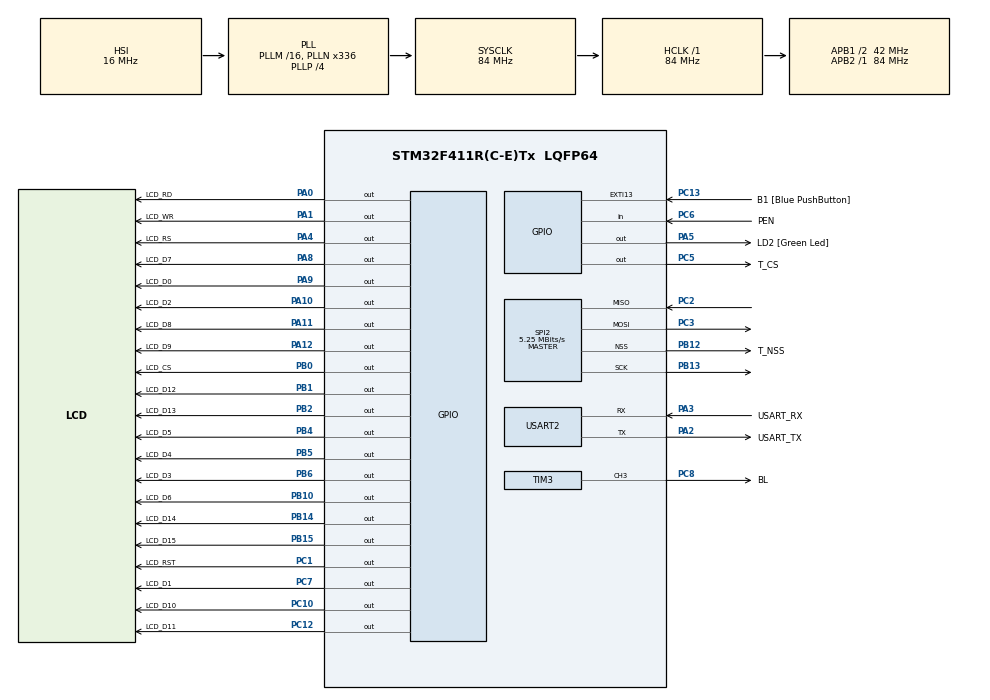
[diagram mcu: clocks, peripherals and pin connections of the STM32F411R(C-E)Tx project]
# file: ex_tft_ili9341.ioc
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Mcu.Family=STM32F4
Mcu.Name=STM32F411R(C-E)Tx
Mcu.Package=LQFP64
NVIC.EXTI15_10_IRQn=true\:0\:0\:false\:false\:true\:true\:true\:true
NVIC.PriorityGroup=NVIC_PRIORITYGROUP_0
NVIC.TIM2_IRQn=true\:0\:0\:false\:false\:true\:true\:true\:true
NVIC.TIM3_IRQn=true\:0\:0\:false\:false\:true\:true\:true\:true
NVIC.USART2_IRQn=true\:0\:0\:false\:false\:true\:true\:true\:true
PA0-WKUP.GPIO_Label=LCD_RD
PA0-WKUP.GPIO_PuPd=GPIO_NOPULL
PA0-WKUP.GPIO_Speed=GPIO_SPEED_FREQ_LOW
PA0-WKUP.Signal=GPIO_Output
PA1.GPIO_Label=LCD_WR
PA1.GPIO_PuPd=GPIO_NOPULL
PA1.GPIO_Speed=GPIO_SPEED_FREQ_LOW
PA1.Signal=GPIO_Output
PA10.GPIO_Label=LCD_D2
PA10.GPIO_PuPd=GPIO_NOPULL
PA10.GPIO_Speed=GPIO_SPEED_FREQ_LOW
PA10.Signal=GPIO_Output
PA11.GPIO_Label=LCD_D8
PA11.GPIO_PuPd=GPIO_NOPULL
PA11.GPIO_Speed=GPIO_SPEED_FREQ_LOW
PA11.Signal=GPIO_Output
PA12.GPIO_Label=LCD_D9
PA12.GPIO_PuPd=GPIO_NOPULL
PA12.GPIO_Speed=GPIO_SPEED_FREQ_LOW
PA12.Signal=GPIO_Output
PA13.GPIO_Label=TMS
PA13.Mode=Serial_Wire
PA13.Signal=SYS_JTMS-SWDIO
PA14.GPIO_Label=TCK
PA14.Mode=Serial_Wire
PA14.Signal=SYS_JTCK-SWCLK
PA2.GPIO_Label=USART_TX
PA2.Mode=Asynchronous
PA2.Signal=USART2_TX
PA3.GPIO_Label=USART_RX
PA3.Mode=Asynchronous
PA3.Signal=USART2_RX
PA4.GPIO_Label=LCD_RS
PA4.GPIO_PuPd=GPIO_NOPULL
PA4.GPIO_Speed=GPIO_SPEED_FREQ_LOW
PA4.Signal=GPIO_Output
PA5.GPIO_Label=LD2 [Green Led]
PA5.Signal=GPIO_Output
PA8.GPIO_Label=LCD_D7
PA8.GPIO_PuPd=GPIO_NOPULL
PA8.GPIO_Speed=GPIO_SPEED_FREQ_LOW
PA8.Signal=GPIO_Output
PA9.GPIO_Label=LCD_D0
PA9.GPIO_PuPd=GPIO_NOPULL
PA9.GPIO_Speed=GPIO_SPEED_FREQ_LOW
PA9.Signal=GPIO_Output
PB0.GPIO_Label=LCD_CS
PB0.GPIO_PuPd=GPIO_NOPULL
PB0.GPIO_Speed=GPIO_SPEED_FREQ_LOW
PB0.Signal=GPIO_Output
PB1.GPIO_Label=LCD_D12
PB1.GPIO_PuPd=GPIO_NOPULL
PB1.GPIO_Speed=GPIO_SPEED_FREQ_LOW
PB1.Signal=GPIO_Output
PB10.GPIO_Label=LCD_D6
PB10.GPIO_PuPd=GPIO_NOPULL
PB10.GPIO_Speed=GPIO_SPEED_FREQ_LOW
PB10.Signal=GPIO_Output
PB12.GPIO_Label=T_NSS
PB12.Mode=NSS_Signal_Hard_Output
PB12.Signal=SPI2_NSS
PB13.Mode=Full_Duplex_Master
PB13.Signal=SPI2_SCK
PB14.GPIO_Label=LCD_D14
PB14.GPIO_PuPd=GPIO_NOPULL
PB14.GPIO_Speed=GPIO_SPEED_FREQ_LOW
PB14.Signal=GPIO_Output
PB15.GPIO_Label=LCD_D15
PB15.GPIO_PuPd=GPIO_NOPULL
PB15.GPIO_Speed=GPIO_SPEED_FREQ_LOW
PB15.Signal=GPIO_Output
PB2.GPIO_Label=LCD_D13
PB2.GPIO_PuPd=GPIO_NOPULL
PB2.GPIO_Speed=GPIO_SPEED_FREQ_LOW
PB2.Signal=GPIO_Output
PB4.GPIO_Label=LCD_D5
PB4.GPIO_PuPd=GPIO_NOPULL
PB4.GPIO_Speed=GPIO_SPEED_FREQ_LOW
PB4.Signal=GPIO_Output
PB5.GPIO_Label=LCD_D4
PB5.GPIO_PuPd=GPIO_NOPULL
PB5.GPIO_Speed=GPIO_SPEED_FREQ_LOW
PB5.Signal=GPIO_Output
PB6.GPIO_Label=LCD_D3
PB6.GPIO_PuPd=GPIO_NOPULL
PB6.Signal=GPIO_Output
PC1.GPIO_Label=LCD_RST
PC1.GPIO_PuPd=GPIO_NOPULL
PC1.GPIO_Speed=GPIO_SPEED_FREQ_LOW
PC1.Signal=GPIO_Output
PC10.GPIO_Label=LCD_D10
PC10.GPIO_PuPd=GPIO_NOPULL
PC10.GPIO_Speed=GPIO_SPEED_FREQ_LOW
PC10.Signal=GPIO_Output
PC12.GPIO_Label=LCD_D11
PC12.GPIO_PuPd=GPIO_NOPULL
PC12.Signal=GPIO_Output
PC13-ANTI_TAMP.GPIO_Label=B1 [Blue PushButton]
PC13-ANTI_TAMP.GPIO_ModeDefaultEXTI=GPIO_MODE_IT_FALLING
PC13-ANTI_TAMP.Signal=GPXTI13
PC14-OSC32_IN.Mode=LSE-External-Oscillator
PC14-OSC32_IN.Signal=RCC_OSC32_IN
PC15-OSC32_OUT.Mode=LSE-External-Oscillator
PC15-OSC32_OUT.Signal=RCC_OSC32_OUT
PC2.Mode=Full_Duplex_Master
PC2.Signal=SPI2_MISO
PC3.Mode=Full_Duplex_Master
PC3.Signal=SPI2_MOSI
PC5.GPIO_Label=T_CS
PC5.GPIO_PuPd=GPIO_NOPULL
PC5.Signal=GPIO_Output
PC6.GPIO_Label=PEN
PC6.GPIO_PuPd=GPIO_NOPULL
PC6.Signal=GPIO_Input
PC7.GPIO_Label=LCD_D1
PC7.GPIO_PuPd=GPIO_NOPULL
PC7.Signal=GPIO_Output
PC8.GPIO_Label=BL
PC8.Signal=S_TIM3_CH3
PH0\ -\ OSC_IN.Mode=HSE-External-Clock-Source
PH0\ -\ OSC_IN.Signal=RCC_OSC_IN
PH1\ -\ OSC_OUT.Mode=HSE-External-Clock-Source
PH1\ -\ OSC_OUT.Signal=RCC_OSC_OUT
ProjectManager.HeapSize=0x200
ProjectManager.StackSize=0x400
ProjectManager.TargetToolchain=STM32CubeIDE
RCC.48MHZClocksFreq_Value=84000000
RCC.AHBFreq_Value=84000000
RCC.APB1CLKDivider=RCC_HCLK_DIV2
RCC.APB1Freq_Value=42000000
RCC.APB1TimFreq_Value=84000000
RCC.APB2Freq_Value=84000000
RCC.APB2TimFreq_Value=84000000
RCC.CortexFreq_Value=84000000
RCC.FLatency-AdvancedSettings=FLASH_LATENCY_2
RCC.HCLKFreq_Value=84000000
RCC.HSE_VALUE=8000000
RCC.HSI_VALUE=16000000
RCC.PLLN=336
RCC.PLLP=RCC_PLLP_DIV4
RCC.SYSCLKFreq_VALUE=84000000
RCC.SYSCLKSource=RCC_SYSCLKSOURCE_PLLCLK
RCC.VCOOutputFreq_Value=336000000
SH.S_TIM3_CH3.0=TIM3_CH3,PWM Generation3 CH3
SPI2.BaudRatePrescaler=SPI_BAUDRATEPRESCALER_8
SPI2.CLKPhase=SPI_PHASE_1EDGE
SPI2.CLKPolarity=SPI_POLARITY_LOW
SPI2.CalculateBaudRate=5.25 MBits/s
SPI2.Direction=SPI_DIRECTION_2LINES
SPI2.Mode=SPI_MODE_MASTER
SPI2.TIMode=SPI_TIMODE_DISABLE
SPI2.VirtualNSS=VM_NSSHARD
SPI2.VirtualType=VM_MASTER
TIM2.Prescaler=84-1
TIM3.Channel-PWM\ Generation3\ CH3=TIM_CHANNEL_3
TIM3.Period=1000
TIM3.Prescaler=84-1
TIM3.Pulse-PWM\ Generation3\ CH3=500
USART2.VirtualMode=VM_ASYNC
VP_TIM2_VS_ClockSourceINT.Mode=Internal
VP_TIM3_VS_ClockSourceINT.Mode=Internal
board=NUCLEO-F411RE

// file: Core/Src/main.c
/* USER CODE BEGIN Header */
/**
  ******************************************************************************
  * @file           : main.c
  * @brief          : Main program body
  ******************************************************************************
  * @attention
  *
  * Copyright (c) 2023 STMicroelectronics.
  * All rights reserved.
  *
  * This software is licensed under terms that can be found in the LICENSE file
  * in the root directory of this software component.
  * If no LICENSE file comes with this software, it is provided AS-IS.
  *
  ******************************************************************************
  */
/* USER CODE END Header */
#include "main.h"

/* USER CODE BEGIN Includes */
#include "app_port.h"

/* USER CODE END Includes */

SPI_HandleTypeDef hspi2;

TIM_HandleTypeDef htim2;
TIM_HandleTypeDef htim3;

UART_HandleTypeDef huart2;

void SystemClock_Config(void);
static void MX_GPIO_Init(void);
static void MX_USART2_UART_Init(void);
static void MX_TIM2_Init(void);
static void MX_SPI2_Init(void);
static void MX_TIM3_Init(void);

int main(void)
{

  /* MCU Configuration--------------------------------------------------------*/

  /* Reset of all peripherals, Initializes the Flash interface and the Systick. */
  HAL_Init();

  /* Configure the system clock */
  SystemClock_Config();

  /* Initialize all configured peripherals */
  MX_GPIO_Init();
  MX_USART2_UART_Init();
  MX_TIM2_Init();
  MX_SPI2_Init();
  MX_TIM3_Init();
  /* USER CODE BEGIN 2 */
	if (!pif_Init(actMicros, portSetup, appSetup)) return -1;

  /* USER CODE END 2 */

  /* Infinite loop */
  /* USER CODE BEGIN WHILE */
  while (1)
  {
	pifTaskManager_Loop();
    /* USER CODE END WHILE */

  }
}

void SystemClock_Config(void)
{
  RCC_OscInitTypeDef RCC_OscInitStruct = {0};
  RCC_ClkInitTypeDef RCC_ClkInitStruct = {0};

  /** Configure the main internal regulator output voltage
  */
  __HAL_RCC_PWR_CLK_ENABLE();
  __HAL_PWR_VOLTAGESCALING_CONFIG(PWR_REGULATOR_VOLTAGE_SCALE1);

  /** Initializes the RCC Oscillators according to the specified parameters
  * in the RCC_OscInitTypeDef structure.
  */
  RCC_OscInitStruct.OscillatorType = RCC_OSCILLATORTYPE_HSI;
  RCC_OscInitStruct.HSIState = RCC_HSI_ON;
  RCC_OscInitStruct.HSICalibrationValue = RCC_HSICALIBRATION_DEFAULT;
  RCC_OscInitStruct.PLL.PLLState = RCC_PLL_ON;
  RCC_OscInitStruct.PLL.PLLSource = RCC_PLLSOURCE_HSI;
  RCC_OscInitStruct.PLL.PLLM = 16;
  RCC_OscInitStruct.PLL.PLLN = 336;
  RCC_OscInitStruct.PLL.PLLP = RCC_PLLP_DIV4;
  RCC_OscInitStruct.PLL.PLLQ = 4;
  if (HAL_RCC_OscConfig(&RCC_OscInitStruct) != HAL_OK)
  {
    Error_Handler();
  }

  /** Initializes the CPU, AHB and APB buses clocks
  */
  RCC_ClkInitStruct.ClockType = RCC_CLOCKTYPE_HCLK|RCC_CLOCKTYPE_SYSCLK
                              |RCC_CLOCKTYPE_PCLK1|RCC_CLOCKTYPE_PCLK2;
  RCC_ClkInitStruct.SYSCLKSource = RCC_SYSCLKSOURCE_PLLCLK;
  RCC_ClkInitStruct.AHBCLKDivider = RCC_SYSCLK_DIV1;
  RCC_ClkInitStruct.APB1CLKDivider = RCC_HCLK_DIV2;
  RCC_ClkInitStruct.APB2CLKDivider = RCC_HCLK_DIV1;

  if (HAL_RCC_ClockConfig(&RCC_ClkInitStruct, FLASH_LATENCY_2) != HAL_OK)
  {
    Error_Handler();
  }
}

static void MX_SPI2_Init(void)
{

  /* SPI2 parameter configuration*/
  hspi2.Instance = SPI2;
  hspi2.Init.Mode = SPI_MODE_MASTER;
  hspi2.Init.Direction = SPI_DIRECTION_2LINES;
  hspi2.Init.DataSize = SPI_DATASIZE_8BIT;
  hspi2.Init.CLKPolarity = SPI_POLARITY_LOW;
  hspi2.Init.CLKPhase = SPI_PHASE_1EDGE;
  hspi2.Init.NSS = SPI_NSS_HARD_OUTPUT;
  hspi2.Init.BaudRatePrescaler = SPI_BAUDRATEPRESCALER_8;
  hspi2.Init.FirstBit = SPI_FIRSTBIT_MSB;
  hspi2.Init.TIMode = SPI_TIMODE_DISABLE;
  hspi2.Init.CRCCalculation = SPI_CRCCALCULATION_DISABLE;
  hspi2.Init.CRCPolynomial = 10;
  if (HAL_SPI_Init(&hspi2) != HAL_OK)
  {
    Error_Handler();
  }

}

static void MX_TIM2_Init(void)
{

  TIM_ClockConfigTypeDef sClockSourceConfig = {0};
  TIM_MasterConfigTypeDef sMasterConfig = {0};

  htim2.Instance = TIM2;
  htim2.Init.Prescaler = 84-1;
  htim2.Init.CounterMode = TIM_COUNTERMODE_UP;
  htim2.Init.Period = 4294967295;
  htim2.Init.ClockDivision = TIM_CLOCKDIVISION_DIV1;
  htim2.Init.AutoReloadPreload = TIM_AUTORELOAD_PRELOAD_DISABLE;
  if (HAL_TIM_Base_Init(&htim2) != HAL_OK)
  {
    Error_Handler();
  }
  sClockSourceConfig.ClockSource = TIM_CLOCKSOURCE_INTERNAL;
  if (HAL_TIM_ConfigClockSource(&htim2, &sClockSourceConfig) != HAL_OK)
  {
    Error_Handler();
  }
  sMasterConfig.MasterOutputTrigger = TIM_TRGO_RESET;
  sMasterConfig.MasterSlaveMode = TIM_MASTERSLAVEMODE_DISABLE;
  if (HAL_TIMEx_MasterConfigSynchronization(&htim2, &sMasterConfig) != HAL_OK)
  {
    Error_Handler();
  }

}

static void MX_TIM3_Init(void)
{

  TIM_ClockConfigTypeDef sClockSourceConfig = {0};
  TIM_MasterConfigTypeDef sMasterConfig = {0};
  TIM_OC_InitTypeDef sConfigOC = {0};

  htim3.Instance = TIM3;
  htim3.Init.Prescaler = 84-1;
  htim3.Init.CounterMode = TIM_COUNTERMODE_UP;
  htim3.Init.Period = 1000;
  htim3.Init.ClockDivision = TIM_CLOCKDIVISION_DIV1;
  htim3.Init.AutoReloadPreload = TIM_AUTORELOAD_PRELOAD_DISABLE;
  if (HAL_TIM_Base_Init(&htim3) != HAL_OK)
  {
    Error_Handler();
  }
  sClockSourceConfig.ClockSource = TIM_CLOCKSOURCE_INTERNAL;
  if (HAL_TIM_ConfigClockSource(&htim3, &sClockSourceConfig) != HAL_OK)
  {
    Error_Handler();
  }
  if (HAL_TIM_PWM_Init(&htim3) != HAL_OK)
  {
    Error_Handler();
  }
  sMasterConfig.MasterOutputTrigger = TIM_TRGO_RESET;
  sMasterConfig.MasterSlaveMode = TIM_MASTERSLAVEMODE_DISABLE;
  if (HAL_TIMEx_MasterConfigSynchronization(&htim3, &sMasterConfig) != HAL_OK)
  {
    Error_Handler();
  }
  sConfigOC.OCMode = TIM_OCMODE_PWM1;
  sConfigOC.Pulse = 500;
  sConfigOC.OCPolarity = TIM_OCPOLARITY_HIGH;
  sConfigOC.OCFastMode = TIM_OCFAST_DISABLE;
  if (HAL_TIM_PWM_ConfigChannel(&htim3, &sConfigOC, TIM_CHANNEL_3) != HAL_OK)
  {
    Error_Handler();
  }
  HAL_TIM_MspPostInit(&htim3);

}

static void MX_USART2_UART_Init(void)
{

  huart2.Instance = USART2;
  huart2.Init.BaudRate = 115200;
  huart2.Init.WordLength = UART_WORDLENGTH_8B;
  huart2.Init.StopBits = UART_STOPBITS_1;
  huart2.Init.Parity = UART_PARITY_NONE;
  huart2.Init.Mode = UART_MODE_TX_RX;
  huart2.Init.HwFlowCtl = UART_HWCONTROL_NONE;
  huart2.Init.OverSampling = UART_OVERSAMPLING_16;
  if (HAL_UART_Init(&huart2) != HAL_OK)
  {
    Error_Handler();
  }

}

static void MX_GPIO_Init(void)
{
  GPIO_InitTypeDef GPIO_InitStruct = {0};

  /* GPIO Ports Clock Enable */
  __HAL_RCC_GPIOC_CLK_ENABLE();
  __HAL_RCC_GPIOH_CLK_ENABLE();
  __HAL_RCC_GPIOA_CLK_ENABLE();
  __HAL_RCC_GPIOB_CLK_ENABLE();

  /*Configure GPIO pin Output Level */
  HAL_GPIO_WritePin(GPIOC, LCD_RST_Pin|T_CS_Pin|LCD_D1_Pin|LCD_D10_Pin
                          |LCD_D11_Pin, GPIO_PIN_RESET);

  /*Configure GPIO pin Output Level */
  HAL_GPIO_WritePin(GPIOA, LCD_RD_Pin|LCD_WR_Pin|LCD_RS_Pin|LD2_Pin
                          |LCD_D7_Pin|LCD_D0_Pin|LCD_D2_Pin|LCD_D8_Pin
                          |LCD_D9_Pin, GPIO_PIN_RESET);

  /*Configure GPIO pin Output Level */
  HAL_GPIO_WritePin(GPIOB, LCD_CS_Pin|LCD_D12_Pin|LCD_D13_Pin|LCD_D6_Pin
                          |LCD_D14_Pin|LCD_D15_Pin|LCD_D5_Pin|LCD_D4_Pin
                          |LCD_D3_Pin, GPIO_PIN_RESET);

  /*Configure GPIO pin : B1_Pin */
  GPIO_InitStruct.Pin = B1_Pin;
  GPIO_InitStruct.Mode = GPIO_MODE_IT_FALLING;
  GPIO_InitStruct.Pull = GPIO_NOPULL;
  HAL_GPIO_Init(B1_GPIO_Port, &GPIO_InitStruct);

  /*Configure GPIO pins : LCD_RST_Pin T_CS_Pin LCD_D1_Pin LCD_D10_Pin
                           LCD_D11_Pin */
  GPIO_InitStruct.Pin = LCD_RST_Pin|T_CS_Pin|LCD_D1_Pin|LCD_D10_Pin
                          |LCD_D11_Pin;
  GPIO_InitStruct.Mode = GPIO_MODE_OUTPUT_PP;
  GPIO_InitStruct.Pull = GPIO_NOPULL;
  GPIO_InitStruct.Speed = GPIO_SPEED_FREQ_LOW;
  HAL_GPIO_Init(GPIOC, &GPIO_InitStruct);

  /*Configure GPIO pins : LCD_RD_Pin LCD_WR_Pin LCD_RS_Pin LD2_Pin
                           LCD_D7_Pin LCD_D0_Pin LCD_D2_Pin LCD_D8_Pin
                           LCD_D9_Pin */
  GPIO_InitStruct.Pin = LCD_RD_Pin|LCD_WR_Pin|LCD_RS_Pin|LD2_Pin
                          |LCD_D7_Pin|LCD_D0_Pin|LCD_D2_Pin|LCD_D8_Pin
                          |LCD_D9_Pin;
  GPIO_InitStruct.Mode = GPIO_MODE_OUTPUT_PP;
  GPIO_InitStruct.Pull = GPIO_NOPULL;
  GPIO_InitStruct.Speed = GPIO_SPEED_FREQ_LOW;
  HAL_GPIO_Init(GPIOA, &GPIO_InitStruct);

  /*Configure GPIO pins : LCD_CS_Pin LCD_D12_Pin LCD_D13_Pin LCD_D6_Pin
                           LCD_D14_Pin LCD_D15_Pin LCD_D5_Pin LCD_D4_Pin
                           LCD_D3_Pin */
  GPIO_InitStruct.Pin = LCD_CS_Pin|LCD_D12_Pin|LCD_D13_Pin|LCD_D6_Pin
                          |LCD_D14_Pin|LCD_D15_Pin|LCD_D5_Pin|LCD_D4_Pin
                          |LCD_D3_Pin;
  GPIO_InitStruct.Mode = GPIO_MODE_OUTPUT_PP;
  GPIO_InitStruct.Pull = GPIO_NOPULL;
  GPIO_InitStruct.Speed = GPIO_SPEED_FREQ_LOW;
  HAL_GPIO_Init(GPIOB, &GPIO_InitStruct);

  /*Configure GPIO pin : PEN_Pin */
  GPIO_InitStruct.Pin = PEN_Pin;
  GPIO_InitStruct.Mode = GPIO_MODE_INPUT;
  GPIO_InitStruct.Pull = GPIO_NOPULL;
  HAL_GPIO_Init(PEN_GPIO_Port, &GPIO_InitStruct);

  /* EXTI interrupt init*/
  HAL_NVIC_SetPriority(EXTI15_10_IRQn, 0, 0);
  HAL_NVIC_EnableIRQ(EXTI15_10_IRQn);

}

void Error_Handler(void)
{
  __disable_irq();
  while (1)
  {
  }
}
